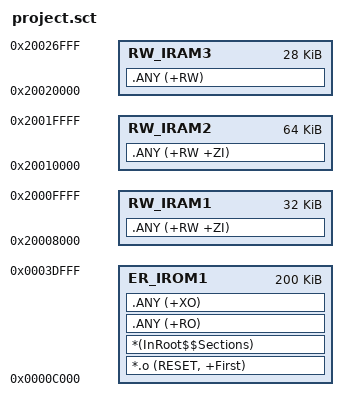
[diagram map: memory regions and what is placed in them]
; *************************************************************
; *** Scatter-Loading Description File generated by uVision ***
; *************************************************************

LR_IROM1 0x0000C000 0x00032000  {    ; load region size_region
  ER_IROM1 0x0000C000 0x00032000  {  ; load address = execution address
   *.o (RESET, +First)
   *(InRoot$$Sections)
   .ANY (+RO)
   .ANY (+XO)
  }
  RW_IRAM1 0x20008000 0x00008000  {  ; RW data
   .ANY (+RW +ZI)
  }
  RW_IRAM2 0x20010000 0x00010000  {  ; RW data
   .ANY (+RW +ZI)
  }
  RW_IRAM3 0x20020000 0x00007000  {  ; RW data, no heap and stack
   .ANY (+RW)
  } 
}

